AUTOSAR XML (schema 4-3-0)
standard types defined: uint8, uint8_DataConstr
package /ComponentTypes
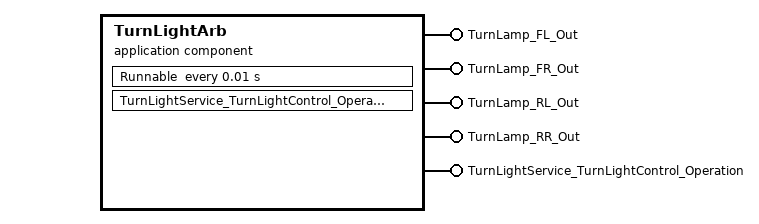
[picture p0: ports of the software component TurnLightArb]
  application sw component type TurnLightArb
    5 x provide port:
      TurnLamp_FL_Out: nonqueued-sender-com-spec{data-element=TurnLamp_FL_Out/Signal, init-value=0}, provided-interface=TurnLamp_FL_Out
      TurnLamp_FR_Out: nonqueued-sender-com-spec{data-element=TurnLamp_FR_Out/Signal, init-value=0}, provided-interface=TurnLamp_FR_Out
      TurnLamp_RL_Out: nonqueued-sender-com-spec{data-element=TurnLamp_RL_Out/Signal, init-value=0}, provided-interface=TurnLamp_RL_Out
      TurnLamp_RR_Out: nonqueued-sender-com-spec{data-element=TurnLamp_RR_Out/Signal, init-value=0}, provided-interface=TurnLamp_RR_Out
      TurnLightService_TurnLightControl_Operation: server-com-spec{operation=Operation, queue-length=1}, provided-interface=TurnLightService_TurnLightControl_Operation
    behavior TurnLightArb_InternalBehavior
      timing event TMT_Runnable: start-on-event=Runnable, period=0.01
      operation invoked event OIT_TurnLightService_TurnLightControl_Operation_Operation_TurnLightService_TurnLightControl_Operation_Operation: start-on-event=TurnLightService_TurnLightControl_Operation_Operation, operation=TurnLightService_TurnLightControl_Operation.Operation
      runnable Runnable
        data-send-points:
          4 x access:
            SEND_TurnLamp_FL_Out_Signal: accessed-variable=TurnLamp_FL_Out.Signal
            SEND_TurnLamp_FR_Out_Signal: accessed-variable=TurnLamp_FR_Out.Signal
            SEND_TurnLamp_RL_Out_Signal: accessed-variable=TurnLamp_RL_Out.Signal
            SEND_TurnLamp_RR_Out_Signal: accessed-variable=TurnLamp_RR_Out.Signal
      runnable TurnLightService_TurnLightControl_Operation_Operation
  swc implementation TurnLightArb_Implementation: behavior=TurnLightArb_InternalBehavior
    code-descriptors:
      code Default: artifact-descriptors=autosar-engineering-object={short-label=Default, category=SWSRC}
package /DataTypes
  impl type TurnLightService_Ctrl_Oeration: category=STRUCTURE, sw-calibration-access=READ-WRITE, type-emitter=RTE
    7 x element, all with category=TYPE_REFERENCE, implementation-data-type=uint8:
      TurnLightPosition: compu {0=NOREQUEST, 1=LEFT, 2=RIGHT, 3=ALL, 4=FRONT_LEFT, 5=MIDDLE_LEFT, 6=REAR_LEFT, 7=FRONT_RIGHT, 8=MIDDLE_RIGHT, 9=REAR_RIGHT, else 0}, invalid-value=0
      TurnLightOnOff: compu {0=NOREQUEST, 1=OFF, 2=ON}, invalid-value=0
      TurnLightDutyCycle: invalid-value=0
      TurnLightCycle
      TurnLightTimes: invalid-value=0
      TurnLightNum
      TurnLightPriority
package /PortInterfaces
  client server interface TurnLightService_TurnLightControl_Operation
    operation Operation
      arg TurnLightCtrlPara: sw-calibration-access=READ-WRITE, type=TurnLightService_Ctrl_Oeration, direction=IN, server-argument-impl-policy=USE-ARGUMENT-TYPE
  4 x sender receiver interface:
    TurnLamp_FL_Out: invalidation-policy{data-element=TurnLamp_FL_Out/Signal, handle-invalid=DONT-INVALIDATE}
      data Signal: type=uint8
    TurnLamp_FR_Out: invalidation-policy{data-element=TurnLamp_FR_Out/Signal, handle-invalid=DONT-INVALIDATE}
      data Signal: type=uint8
    TurnLamp_RL_Out: invalidation-policy{data-element=TurnLamp_RL_Out/Signal, handle-invalid=DONT-INVALIDATE}
      data Signal: type=uint8
    TurnLamp_RR_Out: invalidation-policy{data-element=TurnLamp_RR_Out/Signal, handle-invalid=DONT-INVALIDATE}
      data Signal: type=uint8
